# ime5_target_db register map
Vendor: Texas Instruments
Address unit: 16 bits
Registers are 32-bit, access per field, reset 0x0 unless marked. A register's access mark holds for its fields unless they carry their own. Offsets are as the file gives them; [hi:lo] are bit positions; {n}, {i} and the like mark numbered series; 'fields as' and 'values as' point back to an identical list.

## IME5 (part 2 of 3) — ipxact12_to_ccs_generated
0xF8C __ALL___Mbinfo_part2_MV1 rw — This register contains first motion vector for intermode winner
  [31:0] mvy_mvx — Motion vector
0xF90 __ALL___Mbinfo_part2_MV2 rw — This register contains Second motion vector for intermode winner
  [31:0] mvy_mvx — Motion vector
0xF94 __ALL___Mbinfo_part2_MV3 rw — This register contains Third motion vector for intermode winner
  [31:0] mvy_mvx — Motion vector
0xF98 __ALL___Mbinfo_part2_MV4 rw — This register contains fourth motion vector for intermode winner
  [31:0] mvy_mvx — Motion vector
0xF9C __ALL___Mbinfo_part2_MV5 rw — This register contains fifth motion vector for intermode winner
  [31:0] mvy_mvx — Motion vector
0xFA0 __ALL___Mbinfo_part2_MV6 rw — This register contains sixth motion vector for intermode winner
  [31:0] mvy_mvx — Motion vector
0xFA4 __ALL___Mbinfo_part2_MV7 rw — This register contains seventh motion vector for intermode winner
  [31:0] mvy_mvx — Motion vector
0xFA8 __ALL___Mbinfo_part2_MV8 rw — This register contains eighth motion vector for intermode winner
  [31:0] mvy_mvx — Motion vector
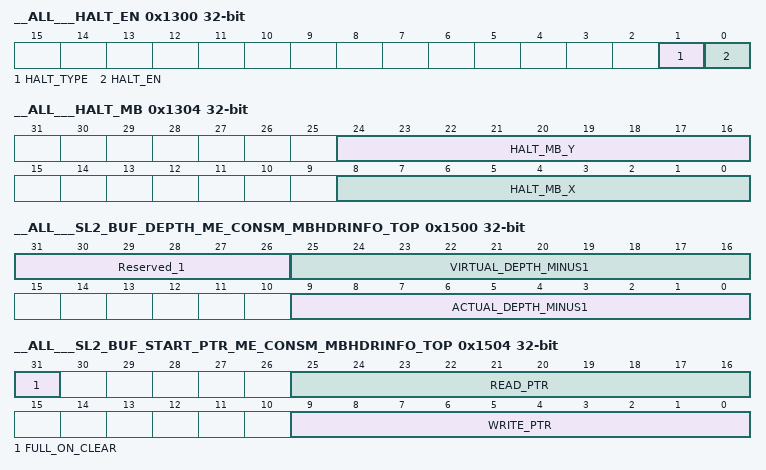
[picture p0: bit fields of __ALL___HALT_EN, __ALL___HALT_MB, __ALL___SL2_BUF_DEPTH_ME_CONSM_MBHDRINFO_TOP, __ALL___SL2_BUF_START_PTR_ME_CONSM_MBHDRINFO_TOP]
0x1300 __ALL___HALT_EN — HALT Enable Control Register
  [1] HALT_TYPE rw — 0: HALT in the beginning; 1: HALT in the end
  [0] HALT_EN rw — Is X-Y HALT enabled
0x1304 __ALL___HALT_MB — HALT MB Register
  [24:16] HALT_MB_Y rw — Y Position of Halt MB
  [8:0] HALT_MB_X rw — X Position of Halt MB
0x1320 __ALL___Debug_1 ro — ME5 Specific Debug Register 1??
0x1400 __ALL___SL2_BUF_ADDR_ME_CONSM_MBHDRINFO_TOP
  [22:0] ADDR rw
0x1404 __ALL___SL2_BUF_ADDR_ME_CONSM_TOP_NEIGHB_MVDATA
  [22:0] ADDR rw
0x1408 __ALL___SL2_BUF_ADDR_ME_PROD_MBINFO_PART1
  [22:0] ADDR rw
0x140C __ALL___SL2_BUF_ADDR_ME_PROD_MBINFO_PART2
  [22:0] ADDR rw
0x1410 __ALL___SL2_BUF_ADDR_ME_PROD_REF_SKIP
  [22:0] ADDR rw
0x1414 __ALL___SL2_BUF_ADDR_ME_CONSM_RL_MBINFO
  [22:0] ADDR rw
0x1418 __ALL___SL2_BUF_ADDR_ME_CONSM_RL_CSRS
  [22:0] ADDR rw
0x141C __ALL___SL2_BUF_ADDR_ME_CONSM_ORG_TILED_YUV_TOP
  [22:0] ADDR rw — Note that for CMB, there is no SL2BC inside ME5, since ME5 is not the last consumer. However, ME5 will still have the base address and read pointer registers.
0x1420 __ALL___SL2_BUF_ADDR_ME_CONSM_ORG_TILED_YUV_BOTTOM
  [22:0] ADDR rw
0x1424 __ALL___SL2_BUF_ADDR_ME_PROD_SPARE_0
  [22:0] ADDR rw
0x1428 __ALL___SL2_BUF_ADDR_ME_PROD_SPARE_1
  [22:0] ADDR rw
{0x142C+4i} __ALL___SL2_BUF_ADDR_ME_CONSM_SPARE_{i} (i=0..2)
  [22:0] ADDR rw
0x1500 __ALL___SL2_BUF_DEPTH_ME_CONSM_MBHDRINFO_TOP
  [31:26] Reserved_1 ro — MBINFO BC related register from IPE5 to ME5
  [25:16] VIRTUAL_DEPTH_MINUS1 rw
  [9:0] ACTUAL_DEPTH_MINUS1 rw
0x1504 __ALL___SL2_BUF_START_PTR_ME_CONSM_MBHDRINFO_TOP
  [31] FULL_ON_CLEAR rw, [25:16] READ_PTR rw, [9:0] WRITE_PTR rw
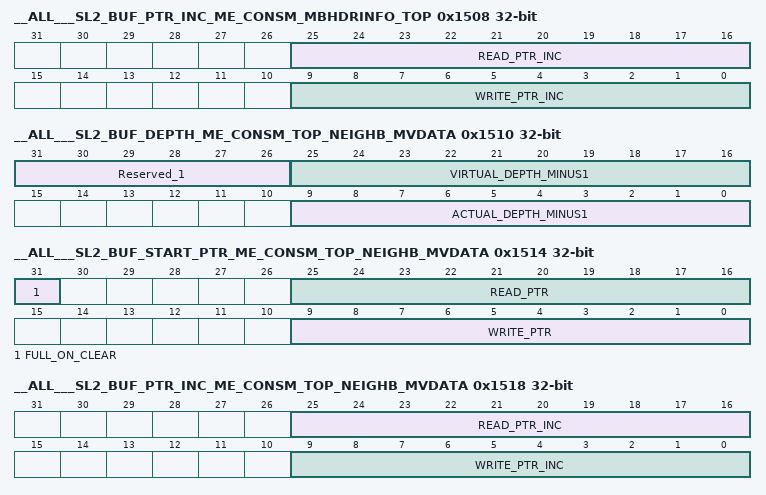
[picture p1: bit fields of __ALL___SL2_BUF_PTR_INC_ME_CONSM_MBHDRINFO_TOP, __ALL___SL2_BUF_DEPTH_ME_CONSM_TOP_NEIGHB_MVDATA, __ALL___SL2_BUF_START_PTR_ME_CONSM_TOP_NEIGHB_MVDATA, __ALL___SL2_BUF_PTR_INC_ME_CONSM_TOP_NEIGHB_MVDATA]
0x1508 __ALL___SL2_BUF_PTR_INC_ME_CONSM_MBHDRINFO_TOP
  [25:16] READ_PTR_INC rw, [9:0] WRITE_PTR_INC rw
0x1510 __ALL___SL2_BUF_DEPTH_ME_CONSM_TOP_NEIGHB_MVDATA
  [31:26] Reserved_1 ro — TOP MVP INFO BC related register from ECD5 to ME5
  [25:16] VIRTUAL_DEPTH_MINUS1 rw
  [9:0] ACTUAL_DEPTH_MINUS1 rw
0x1514 __ALL___SL2_BUF_START_PTR_ME_CONSM_TOP_NEIGHB_MVDATA
  [31] FULL_ON_CLEAR rw, [25:16] READ_PTR rw, [9:0] WRITE_PTR rw
0x1518 __ALL___SL2_BUF_PTR_INC_ME_CONSM_TOP_NEIGHB_MVDATA
  [25:16] READ_PTR_INC rw, [9:0] WRITE_PTR_INC rw
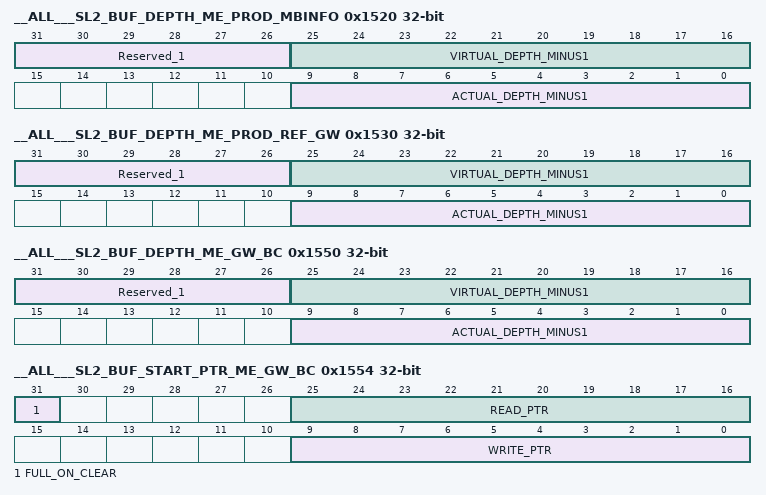
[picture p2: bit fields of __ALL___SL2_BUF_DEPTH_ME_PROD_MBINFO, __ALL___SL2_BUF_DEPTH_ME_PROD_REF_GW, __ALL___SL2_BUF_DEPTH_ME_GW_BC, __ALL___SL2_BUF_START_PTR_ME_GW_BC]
0x1520 __ALL___SL2_BUF_DEPTH_ME_PROD_MBINFO
  [31:26] Reserved_1 ro — MBINFO OUTPUT BC In producer sl2bcs, we don’t need start read pointer. Only start write pointer is required.
  [25:16] VIRTUAL_DEPTH_MINUS1 rw
  [9:0] ACTUAL_DEPTH_MINUS1 rw
0x1524 __ALL___SL2_BUF_START_PTR_ME_PROD_MBINFO
  [9:0] WRITE_PTR rw
0x1528 __ALL___SL2_BUF_PTR_INC_ME_PROD_MBINFO
  [9:0] WRITE_PTR_INC rw
0x1530 __ALL___SL2_BUF_DEPTH_ME_PROD_REF_GW
  [31:26] Reserved_1 ro — GW BC to MC In producer sl2bcs, we don’t need start read pointer. Only start write pointer is required.
  [25:16] VIRTUAL_DEPTH_MINUS1 rw
  [9:0] ACTUAL_DEPTH_MINUS1 rw
0x1534 __ALL___SL2_BUF_START_PTR_ME_PROD_REF_GW
  [9:0] WRITE_PTR rw
0x1538 __ALL___SL2_BUF_PTR_INC_ME_PROD_REF_GW
  [9:0] WRITE_PTR_INC rw
0x1550 __ALL___SL2_BUF_DEPTH_ME_GW_BC
  [31:26] Reserved_1 ro — Internal BC for GW between ME5 CORE and VIM thread
  [25:16] VIRTUAL_DEPTH_MINUS1 rw
  [9:0] ACTUAL_DEPTH_MINUS1 rw
0x1554 __ALL___SL2_BUF_START_PTR_ME_GW_BC
  [31] FULL_ON_CLEAR rw, [25:16] READ_PTR rw, [9:0] WRITE_PTR rw
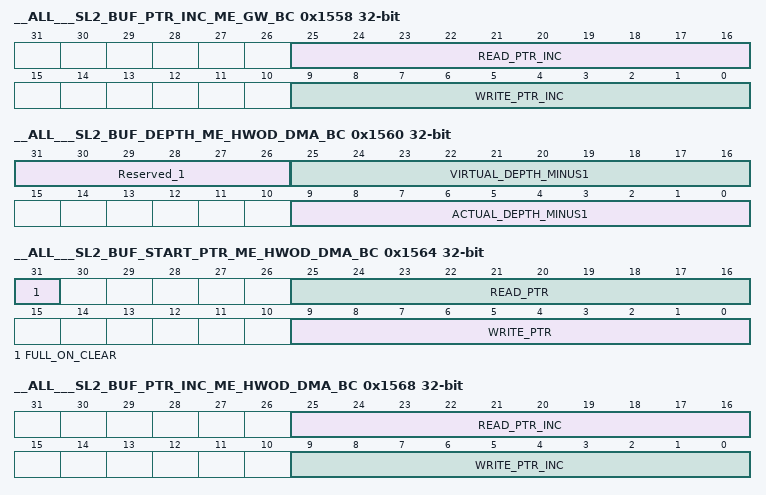
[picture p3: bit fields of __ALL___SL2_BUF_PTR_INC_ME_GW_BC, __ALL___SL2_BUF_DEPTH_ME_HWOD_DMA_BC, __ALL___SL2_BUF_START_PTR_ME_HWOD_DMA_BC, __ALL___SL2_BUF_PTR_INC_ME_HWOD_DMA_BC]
0x1558 __ALL___SL2_BUF_PTR_INC_ME_GW_BC
  [25:16] READ_PTR_INC rw, [9:0] WRITE_PTR_INC rw
0x1560 __ALL___SL2_BUF_DEPTH_ME_HWOD_DMA_BC
  [31:26] Reserved_1 ro — Internal BC for HWOD DMA between ME5 CORE and VIM thread
  [25:16] VIRTUAL_DEPTH_MINUS1 rw
  [9:0] ACTUAL_DEPTH_MINUS1 rw
0x1564 __ALL___SL2_BUF_START_PTR_ME_HWOD_DMA_BC
  [31] FULL_ON_CLEAR rw, [25:16] READ_PTR rw, [9:0] WRITE_PTR rw
0x1568 __ALL___SL2_BUF_PTR_INC_ME_HWOD_DMA_BC
  [25:16] READ_PTR_INC rw, [9:0] WRITE_PTR_INC rw
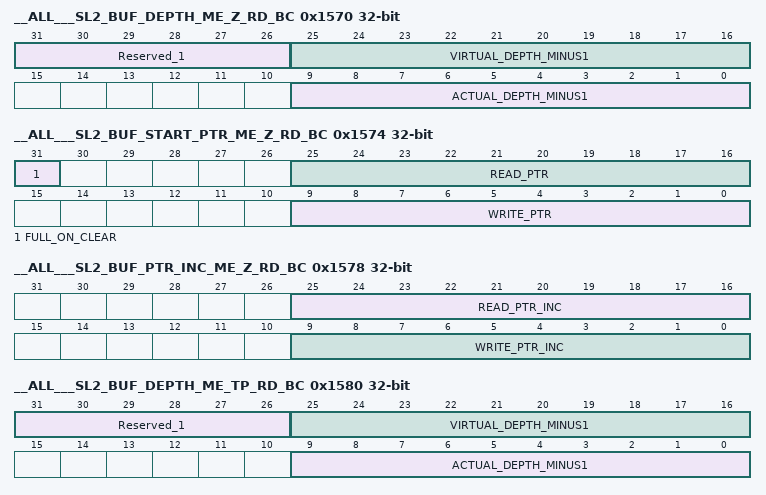
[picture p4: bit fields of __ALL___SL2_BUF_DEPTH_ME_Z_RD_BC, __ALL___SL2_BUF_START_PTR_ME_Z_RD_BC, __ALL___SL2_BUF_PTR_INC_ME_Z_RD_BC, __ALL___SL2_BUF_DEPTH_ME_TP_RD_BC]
0x1570 __ALL___SL2_BUF_DEPTH_ME_Z_RD_BC
  [31:26] Reserved_1 ro — Internal BC for ZFLAG Reads between ME5 CORE and VIM thread
  [25:16] VIRTUAL_DEPTH_MINUS1 rw
  [9:0] ACTUAL_DEPTH_MINUS1 rw
0x1574 __ALL___SL2_BUF_START_PTR_ME_Z_RD_BC
  [31] FULL_ON_CLEAR rw, [25:16] READ_PTR rw, [9:0] WRITE_PTR rw
0x1578 __ALL___SL2_BUF_PTR_INC_ME_Z_RD_BC
  [25:16] READ_PTR_INC rw, [9:0] WRITE_PTR_INC rw
0x1580 __ALL___SL2_BUF_DEPTH_ME_TP_RD_BC
  [31:26] Reserved_1 ro — Internal BC for TP Reads between ME5 CORE and VIM thread
  [25:16] VIRTUAL_DEPTH_MINUS1 rw
  [9:0] ACTUAL_DEPTH_MINUS1 rw
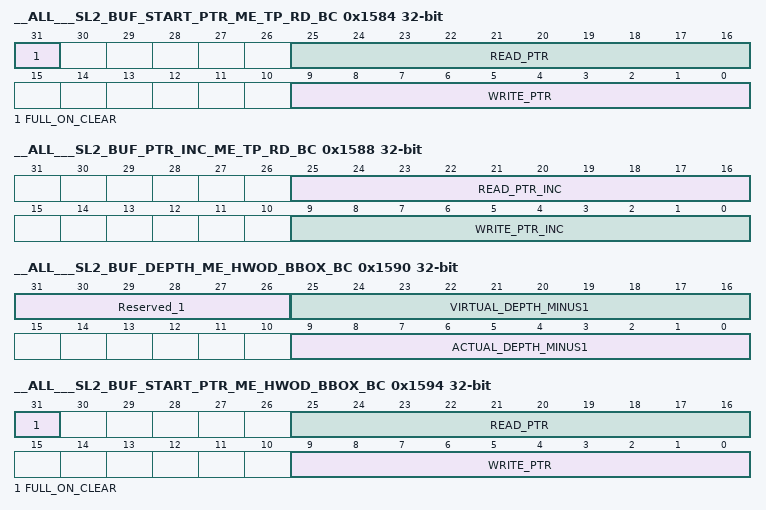
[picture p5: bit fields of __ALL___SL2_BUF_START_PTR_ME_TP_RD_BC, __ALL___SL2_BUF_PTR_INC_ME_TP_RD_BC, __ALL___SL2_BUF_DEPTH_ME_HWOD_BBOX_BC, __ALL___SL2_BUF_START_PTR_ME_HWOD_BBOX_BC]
0x1584 __ALL___SL2_BUF_START_PTR_ME_TP_RD_BC
  [31] FULL_ON_CLEAR rw, [25:16] READ_PTR rw, [9:0] WRITE_PTR rw
0x1588 __ALL___SL2_BUF_PTR_INC_ME_TP_RD_BC
  [25:16] READ_PTR_INC rw, [9:0] WRITE_PTR_INC rw
0x158C __ALL___SL2_BUF_RD_THRESHOLD_ME_TP_RD_BC
  [9:0] RD_THRESHOLD rw — bc_ready for the read side is asserted only if the number of filled BUFFER_ENTRYs is more than or equal to the rd_threshold. rd_threshold >= rd_pointer_inc
0x1590 __ALL___SL2_BUF_DEPTH_ME_HWOD_BBOX_BC
  [31:26] Reserved_1 ro — Internal BC for HWOD BOX between ME5 CORE and VIM thread
  [25:16] VIRTUAL_DEPTH_MINUS1 rw
  [9:0] ACTUAL_DEPTH_MINUS1 rw
0x1594 __ALL___SL2_BUF_START_PTR_ME_HWOD_BBOX_BC
  [31] FULL_ON_CLEAR rw, [25:16] READ_PTR rw, [9:0] WRITE_PTR rw
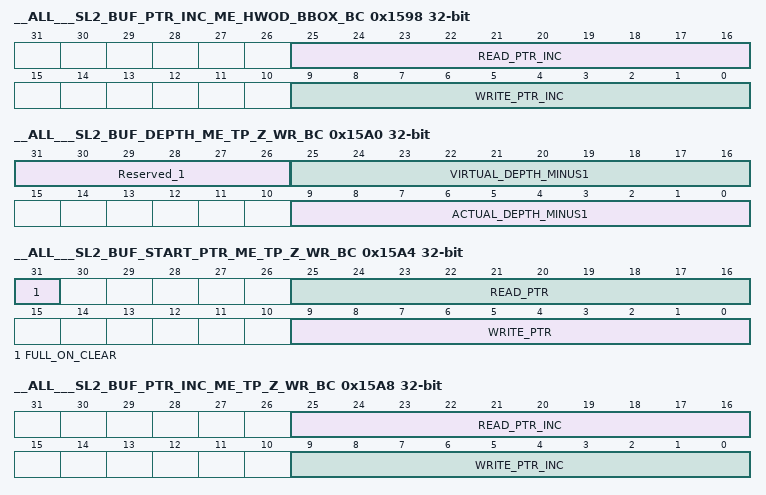
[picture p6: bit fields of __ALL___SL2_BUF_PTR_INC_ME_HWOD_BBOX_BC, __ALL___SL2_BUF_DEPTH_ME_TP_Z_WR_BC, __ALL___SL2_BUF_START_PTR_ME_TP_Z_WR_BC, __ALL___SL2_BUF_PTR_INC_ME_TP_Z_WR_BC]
0x1598 __ALL___SL2_BUF_PTR_INC_ME_HWOD_BBOX_BC
  [25:16] READ_PTR_INC rw, [9:0] WRITE_PTR_INC rw
0x15A0 __ALL___SL2_BUF_DEPTH_ME_TP_Z_WR_BC
  [31:26] Reserved_1 ro — Internal BC forZ flag writes as well as TP writes between ME5 CORE and VIM thread
  [25:16] VIRTUAL_DEPTH_MINUS1 rw
  [9:0] ACTUAL_DEPTH_MINUS1 rw
0x15A4 __ALL___SL2_BUF_START_PTR_ME_TP_Z_WR_BC
  [31] FULL_ON_CLEAR rw, [25:16] READ_PTR rw, [9:0] WRITE_PTR rw
0x15A8 __ALL___SL2_BUF_PTR_INC_ME_TP_Z_WR_BC
  [25:16] READ_PTR_INC rw, [9:0] WRITE_PTR_INC rw
0x15AC __ALL___SL2_BUF_RD_THRESHOLD_ME_TP_Z_WR_BC
  fields as __ALL___SL2_BUF_RD_THRESHOLD_ME_TP_RD_BC
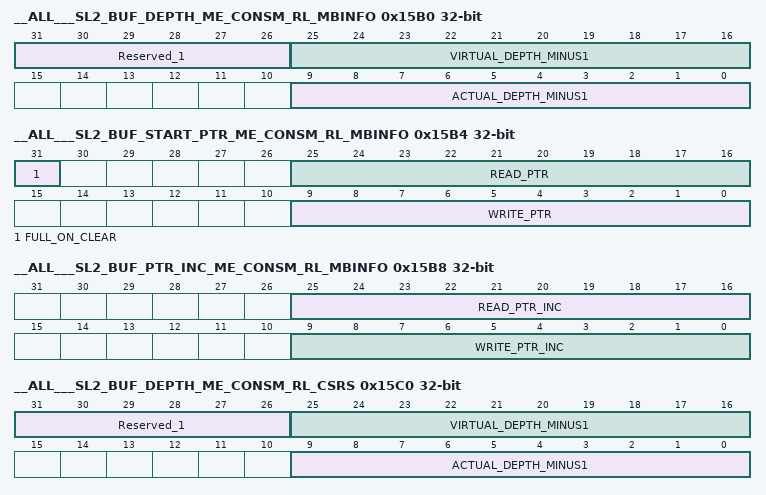
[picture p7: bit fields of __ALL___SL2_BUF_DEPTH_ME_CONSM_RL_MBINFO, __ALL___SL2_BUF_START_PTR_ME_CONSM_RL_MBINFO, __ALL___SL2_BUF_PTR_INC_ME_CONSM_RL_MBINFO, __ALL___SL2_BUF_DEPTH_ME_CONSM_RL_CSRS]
0x15B0 __ALL___SL2_BUF_DEPTH_ME_CONSM_RL_MBINFO
  [31:26] Reserved_1 ro — BC for SVC Reference Layer MBINFO
  [25:16] VIRTUAL_DEPTH_MINUS1 rw
  [9:0] ACTUAL_DEPTH_MINUS1 rw
0x15B4 __ALL___SL2_BUF_START_PTR_ME_CONSM_RL_MBINFO
  [31] FULL_ON_CLEAR rw, [25:16] READ_PTR rw, [9:0] WRITE_PTR rw
0x15B8 __ALL___SL2_BUF_PTR_INC_ME_CONSM_RL_MBINFO
  [25:16] READ_PTR_INC rw, [9:0] WRITE_PTR_INC rw
0x15C0 __ALL___SL2_BUF_DEPTH_ME_CONSM_RL_CSRS
  [31:26] Reserved_1 ro — BC for SVC Reference Layer Data
  [25:16] VIRTUAL_DEPTH_MINUS1 rw
  [9:0] ACTUAL_DEPTH_MINUS1 rw
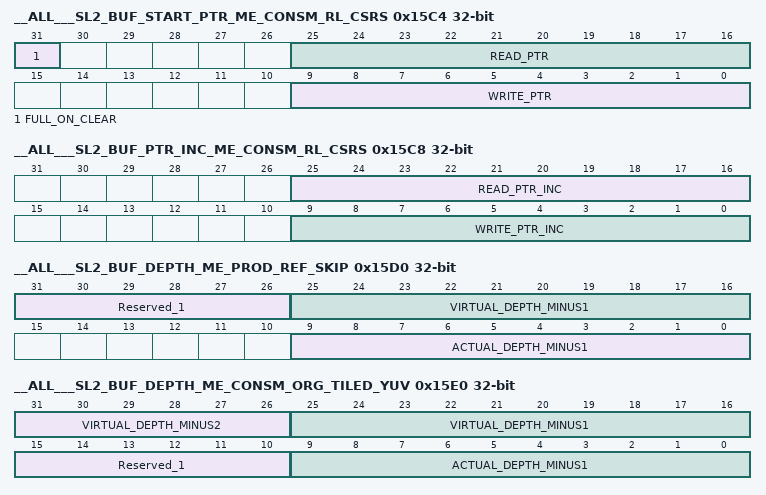
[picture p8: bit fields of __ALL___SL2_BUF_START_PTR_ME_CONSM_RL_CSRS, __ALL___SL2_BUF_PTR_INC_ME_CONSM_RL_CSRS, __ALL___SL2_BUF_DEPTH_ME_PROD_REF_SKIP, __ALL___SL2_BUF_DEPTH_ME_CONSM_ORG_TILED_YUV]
0x15C4 __ALL___SL2_BUF_START_PTR_ME_CONSM_RL_CSRS
  [31] FULL_ON_CLEAR rw, [25:16] READ_PTR rw, [9:0] WRITE_PTR rw
0x15C8 __ALL___SL2_BUF_PTR_INC_ME_CONSM_RL_CSRS
  [25:16] READ_PTR_INC rw, [9:0] WRITE_PTR_INC rw
0x15D0 __ALL___SL2_BUF_DEPTH_ME_PROD_REF_SKIP
  [31:26] Reserved_1 ro — BC for SKOB output from ME to MC
  [25:16] VIRTUAL_DEPTH_MINUS1 rw
  [9:0] ACTUAL_DEPTH_MINUS1 rw
0x15D4 __ALL___SL2_BUF_START_PTR_ME_PROD_REF_SKIP
  [9:0] WRITE_PTR rw
0x15D8 __ALL___SL2_BUF_PTR_INC_ME_PROD_REF_SKIP
  [9:0] WRITE_PTR_INC rw
0x15E0 __ALL___SL2_BUF_DEPTH_ME_CONSM_ORG_TILED_YUV
  [31:26] VIRTUAL_DEPTH_MINUS2 ro
  [25:16] VIRTUAL_DEPTH_MINUS1 rw
  [15:10] Reserved_1 ro — BC related registers for CMB. There is no BC exists Size by which READ_PTR of to be incremented on the falling edge of rd_core_busy
  [9:0] ACTUAL_DEPTH_MINUS1 rw
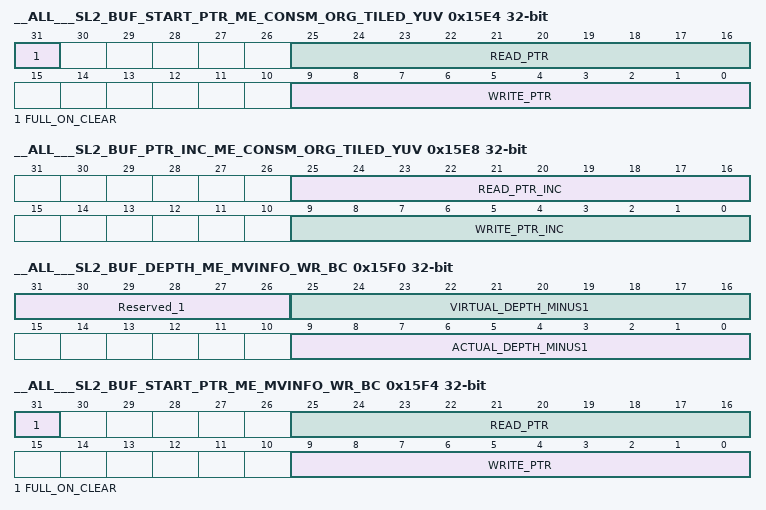
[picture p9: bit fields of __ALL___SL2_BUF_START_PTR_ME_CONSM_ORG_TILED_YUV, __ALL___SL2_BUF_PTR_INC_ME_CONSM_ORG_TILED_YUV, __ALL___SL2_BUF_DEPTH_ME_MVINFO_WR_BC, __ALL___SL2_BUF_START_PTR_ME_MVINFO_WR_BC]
0x15E4 __ALL___SL2_BUF_START_PTR_ME_CONSM_ORG_TILED_YUV
  [31] FULL_ON_CLEAR rw, [25:16] READ_PTR rw, [9:0] WRITE_PTR rw
0x15E8 __ALL___SL2_BUF_PTR_INC_ME_CONSM_ORG_TILED_YUV
  [25:16] READ_PTR_INC rw, [9:0] WRITE_PTR_INC rw
0x15F0 __ALL___SL2_BUF_DEPTH_ME_MVINFO_WR_BC
  fields as __ALL___SL2_BUF_DEPTH_ME_GW_BC
0x15F4 __ALL___SL2_BUF_START_PTR_ME_MVINFO_WR_BC
  [31] FULL_ON_CLEAR rw, [25:16] READ_PTR rw, [9:0] WRITE_PTR rw
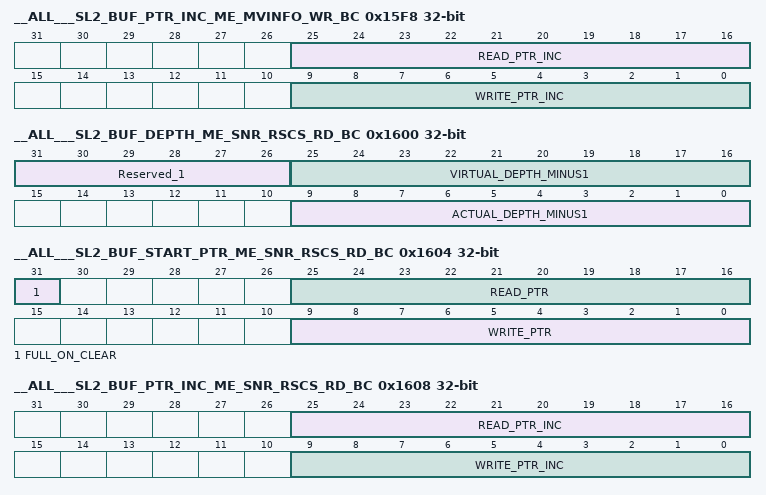
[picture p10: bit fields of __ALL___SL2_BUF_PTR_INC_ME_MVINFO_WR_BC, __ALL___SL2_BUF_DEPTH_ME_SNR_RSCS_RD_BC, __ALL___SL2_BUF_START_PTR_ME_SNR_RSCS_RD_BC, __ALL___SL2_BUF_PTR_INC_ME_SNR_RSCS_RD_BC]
0x15F8 __ALL___SL2_BUF_PTR_INC_ME_MVINFO_WR_BC
  [25:16] READ_PTR_INC rw, [9:0] WRITE_PTR_INC rw
0x1600 __ALL___SL2_BUF_DEPTH_ME_SNR_RSCS_RD_BC
  fields as __ALL___SL2_BUF_DEPTH_ME_GW_BC
0x1604 __ALL___SL2_BUF_START_PTR_ME_SNR_RSCS_RD_BC
  [31] FULL_ON_CLEAR rw, [25:16] READ_PTR rw, [9:0] WRITE_PTR rw
0x1608 __ALL___SL2_BUF_PTR_INC_ME_SNR_RSCS_RD_BC
  [25:16] READ_PTR_INC rw, [9:0] WRITE_PTR_INC rw
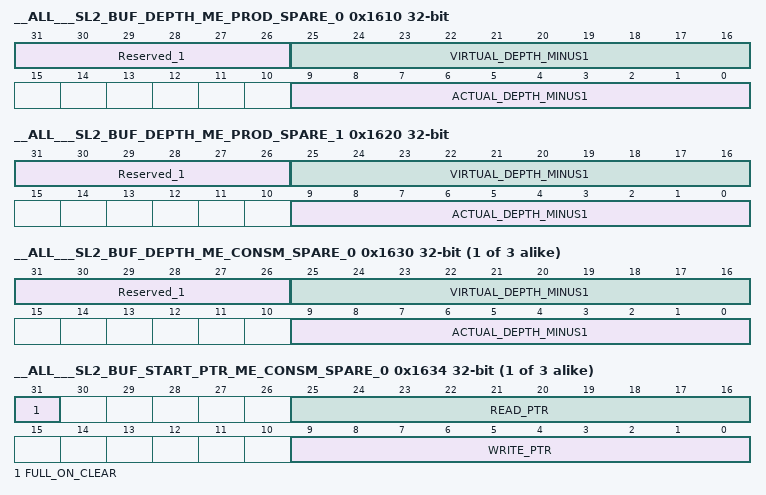
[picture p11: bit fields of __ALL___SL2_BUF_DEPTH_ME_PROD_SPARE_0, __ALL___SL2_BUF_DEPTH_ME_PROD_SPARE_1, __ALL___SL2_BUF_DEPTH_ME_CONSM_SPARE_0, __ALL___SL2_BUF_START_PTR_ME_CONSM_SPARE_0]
0x1610 __ALL___SL2_BUF_DEPTH_ME_PROD_SPARE_0
  [31:26] Reserved_1 ro — Spare BC for Producer
  [25:16] VIRTUAL_DEPTH_MINUS1 rw
  [9:0] ACTUAL_DEPTH_MINUS1 rw
0x1614 __ALL___SL2_BUF_START_PTR_ME_PROD_SPARE_0
  [9:0] WRITE_PTR rw
0x1618 __ALL___SL2_BUF_PTR_INC_ME_PROD_SPARE_0
  [9:0] WRITE_PTR_INC rw
0x1620 __ALL___SL2_BUF_DEPTH_ME_PROD_SPARE_1
  fields as __ALL___SL2_BUF_DEPTH_ME_PROD_SPARE_0
0x1624 __ALL___SL2_BUF_START_PTR_ME_PROD_SPARE_1
  [9:0] WRITE_PTR rw
0x1628 __ALL___SL2_BUF_PTR_INC_ME_PROD_SPARE_1
  [9:0] WRITE_PTR_INC rw
{0x1630+0x10*i} __ALL___SL2_BUF_DEPTH_ME_CONSM_SPARE_{i} (i=0..2)
  [31:26] Reserved_1 ro — Spare BC for Consumer
  [25:16] VIRTUAL_DEPTH_MINUS1 rw
  [9:0] ACTUAL_DEPTH_MINUS1 rw
{0x1634+0x10*i} __ALL___SL2_BUF_START_PTR_ME_CONSM_SPARE_{i} (i=0..2)
  [31] FULL_ON_CLEAR rw, [25:16] READ_PTR rw, [9:0] WRITE_PTR rw
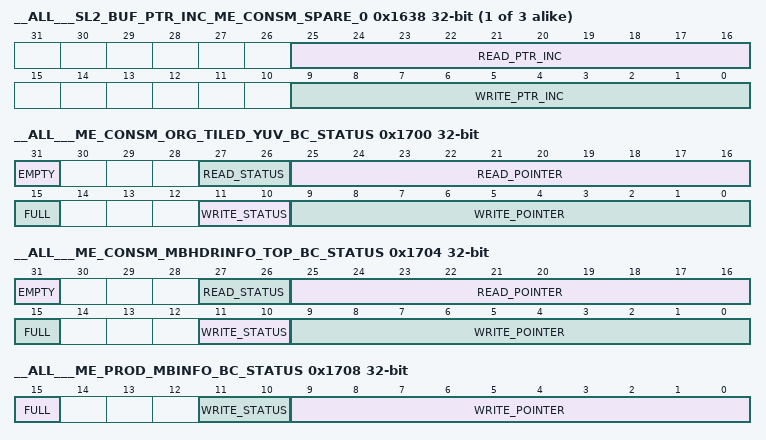
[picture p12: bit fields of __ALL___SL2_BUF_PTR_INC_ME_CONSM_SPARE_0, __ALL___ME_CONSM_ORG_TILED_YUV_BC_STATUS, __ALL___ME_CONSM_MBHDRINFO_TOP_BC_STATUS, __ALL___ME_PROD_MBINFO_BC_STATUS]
{0x1638+0x10*i} __ALL___SL2_BUF_PTR_INC_ME_CONSM_SPARE_{i} (i=0..2)
  [25:16] READ_PTR_INC rw, [9:0] WRITE_PTR_INC rw
0x1700 __ALL___ME_CONSM_ORG_TILED_YUV_BC_STATUS ro
  [31] EMPTY, [27:26] READ_STATUS, [25:16] READ_POINTER, [15] FULL, [11:10] WRITE_STATUS, [9:0] WRITE_POINTER
0x1704 __ALL___ME_CONSM_MBHDRINFO_TOP_BC_STATUS ro
  fields as __ALL___ME_CONSM_ORG_TILED_YUV_BC_STATUS
0x1708 __ALL___ME_PROD_MBINFO_BC_STATUS ro
  [15] FULL, [11:10] WRITE_STATUS, [9:0] WRITE_POINTER
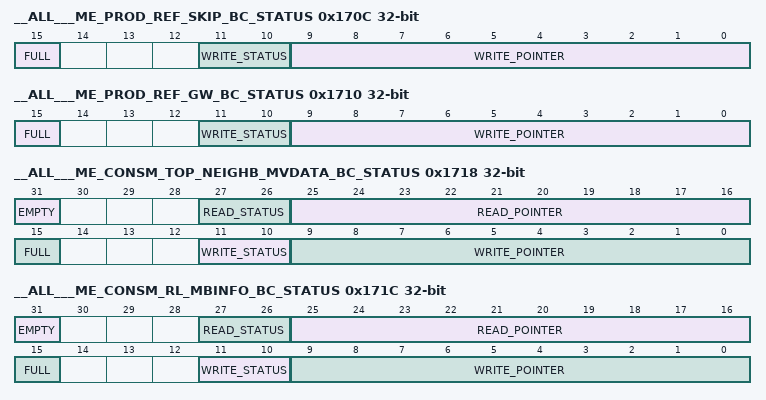
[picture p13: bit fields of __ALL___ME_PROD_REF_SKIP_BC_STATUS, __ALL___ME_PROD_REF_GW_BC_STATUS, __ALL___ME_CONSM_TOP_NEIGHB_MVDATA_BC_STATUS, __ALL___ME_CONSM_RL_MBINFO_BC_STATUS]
0x170C __ALL___ME_PROD_REF_SKIP_BC_STATUS ro
  [15] FULL, [11:10] WRITE_STATUS, [9:0] WRITE_POINTER
0x1710 __ALL___ME_PROD_REF_GW_BC_STATUS ro
  [15] FULL, [11:10] WRITE_STATUS, [9:0] WRITE_POINTER
0x1718 __ALL___ME_CONSM_TOP_NEIGHB_MVDATA_BC_STATUS ro
  fields as __ALL___ME_CONSM_ORG_TILED_YUV_BC_STATUS
0x171C __ALL___ME_CONSM_RL_MBINFO_BC_STATUS ro
  fields as __ALL___ME_CONSM_ORG_TILED_YUV_BC_STATUS
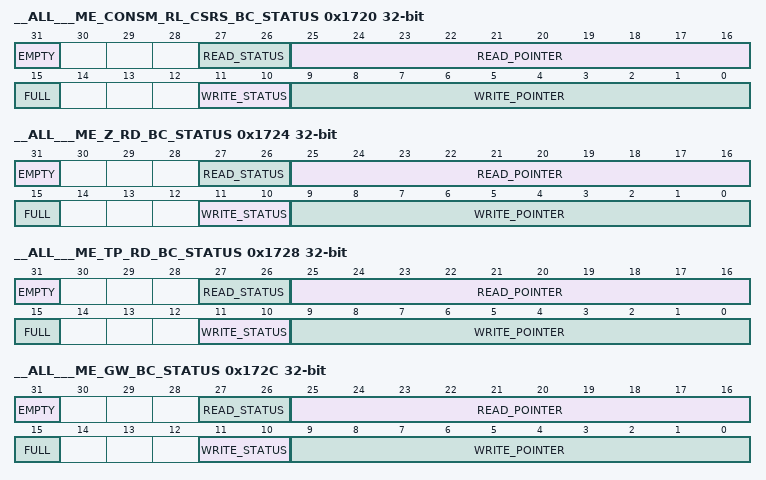
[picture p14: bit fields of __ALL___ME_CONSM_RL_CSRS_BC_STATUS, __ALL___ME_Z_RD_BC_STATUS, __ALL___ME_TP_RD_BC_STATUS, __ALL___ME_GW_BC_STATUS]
0x1720 __ALL___ME_CONSM_RL_CSRS_BC_STATUS ro
  fields as __ALL___ME_CONSM_ORG_TILED_YUV_BC_STATUS
0x1724 __ALL___ME_Z_RD_BC_STATUS ro
  fields as __ALL___ME_CONSM_ORG_TILED_YUV_BC_STATUS
0x1728 __ALL___ME_TP_RD_BC_STATUS ro
  fields as __ALL___ME_CONSM_ORG_TILED_YUV_BC_STATUS
0x172C __ALL___ME_GW_BC_STATUS ro
  fields as __ALL___ME_CONSM_ORG_TILED_YUV_BC_STATUS
0x1730 __ALL___ME_HWOD_BBOX_BC_STATUS ro
  fields as __ALL___ME_CONSM_ORG_TILED_YUV_BC_STATUS
0x1734 __ALL___ME_HWOD_DMA_BC_STATUS ro
  fields as __ALL___ME_CONSM_ORG_TILED_YUV_BC_STATUS
0x1738 __ALL___ME_Z_WR_BC_STATUS ro
  fields as __ALL___ME_CONSM_ORG_TILED_YUV_BC_STATUS
0x173C __ALL___ME_SNR_RSCS_RD_BC_STATUS ro
  fields as __ALL___ME_CONSM_ORG_TILED_YUV_BC_STATUS
0x1740 __ALL___ME_MVINFO_WR_BC_STATUS ro
  fields as __ALL___ME_CONSM_ORG_TILED_YUV_BC_STATUS
0x1744 __ALL___ME_PROD_SPARE_0_BC_STATUS ro
  [15] FULL, [11:10] WRITE_STATUS, [9:0] WRITE_POINTER
0x1748 __ALL___ME_PROD_SPARE_1_BC_STATUS ro
  [15] FULL, [11:10] WRITE_STATUS, [9:0] WRITE_POINTER
{0x174C+4i} __ALL___ME_CONSM_SPARE_{i}_BC_STATUS ro (i=0..2)
  fields as __ALL___ME_CONSM_ORG_TILED_YUV_BC_STATUS
0x1800 __ALL___PID ro — ME5 PID
0x1804 __ALL___SYSCONFIG
  [5:4] STANDBYMODE rw
  [3:2] IDLE_MODE rw
  [1] FREE_EMU rw — sensitivity to emulation suspend (suspend is same as halt?)
  [0] SOFT_RESET rw
0x1808 __ALL___IRQ_EOI ro
  [0] IRQ_EOI
0x180C __ALL___IRQ_STATUS_RAW
  [23] DM_DONE rw, [22] MB_COUNT_INT_2 rw, [21] MB_COUNT_INT_1 rw, [20] GW_nMB_Done rw, [19] END_OF_MB rw, [18] END_OF_PIPE rw, [17] END_OF_SLICE rw, [16] END_OF_ROW rw, [15:8] GPI9_16 rw, [7:1] GPI2_8 rw, [0] GPI1 rw
0x1810 __ALL___IRQ_STATUS
  fields as __ALL___IRQ_STATUS_RAW
0x1814 __ALL___IRQ_ENABLE_SET
  fields as __ALL___IRQ_STATUS_RAW
0x1818 __ALL___IRQ_ENABLE_CLR
  fields as __ALL___IRQ_STATUS_RAW
0x181C __ALL___IRQ_BLOCKING_CFG
  fields as __ALL___IRQ_STATUS_RAW
0x1820 __ALL___CFPB_START — CFPB Start Address
  [22:0] FPB_start rw
0x1824 __ALL___SCHEDULER_STATUS ro — Shedulaer Status
  [20] STEPPING, [19] RESUMING, [18] HALTED, [17] CPU_HALTING, [16] THRD_HALTING, [12] RESUME_ACK, [11] RESUME, [10] REWIND, [9] WAIT_4_FUNC_IDLE, [8] EOP, [3] THREAD_EXE, [2] INIT_ACK, [1] HWA_INIT, [0] FUNC_IDLE
0x1828 __ALL___HWA_THREAD_STATUS_CORE ro — Thread Status for core thread
  [7] HALT_ABORT, [6] HALT_DEBUG, [5] HALT_REWIND, [4] HALT_PIPEDOWN, [3] HALT_INTR, [2] EXE, [1] WAIT, [0] IDLE
0x182C __ALL___HWA_THREAD_STATUS_PREFETCH ro — Thread Status for prefetch thread
  fields as __ALL___HWA_THREAD_STATUS_CORE
0x1830 __ALL___HWA_THREAD_STATUS_Z_RD ro — Thread Status for Z_RD thread
  fields as __ALL___HWA_THREAD_STATUS_CORE
0x1834 __ALL___HWA_THREAD_STATUS_TP_RD ro — Thread Status for TP_RD thread
  fields as __ALL___HWA_THREAD_STATUS_CORE
0x1838 __ALL___HWA_THREAD_STATUS_TP_Z_WR ro — Thread Status for TP Z WR thread
  fields as __ALL___HWA_THREAD_STATUS_CORE
0x183C __ALL___HWA_THREAD_STATUS_HWOD_BBOX ro — Thread Status for HWOD_BBOX thread
  fields as __ALL___HWA_THREAD_STATUS_CORE
0x1840 __ALL___HWA_THREAD_STATUS_GW ro — Thread Status for GW thread
  fields as __ALL___HWA_THREAD_STATUS_CORE
0x1844 __ALL___HWA_THREAD_STATUS_HWOD_DMA ro — Thread Status for HWOD DMA thread
  fields as __ALL___HWA_THREAD_STATUS_CORE
0x1848 __ALL___HWA_THREAD_STATUS_MVINFO ro — Thread Status for RL MVINFO thread
  fields as __ALL___HWA_THREAD_STATUS_CORE
0x184C __ALL___HWA_THREAD_STATUS_SNR_RSCS ro — Thread Status for SNR RS CS thread
  fields as __ALL___HWA_THREAD_STATUS_CORE
0x1880 __ALL___ME5_ARP32_RESET — ME5 T16 reset control
  [0] ME5_ARP32_reset rw
0x1884 __ALL___BC_CLEAR — BC clear register for SL2BC
  [19] ME_CONSM_ORG_TILED_YUV_BC_CLEAR wo, [18] ME_CONSM_MBHDRINFO_TOP_BC_CLEAR wo, [17] ME_PROD_MBINFO_BC_CLEAR wo, [16] ME_PROD_REF_SKIP_BC_CLEAR wo, [15] ME_PROD_REF_GW_BC_CLEAR wo, [13] ME_CONSM_TOP_NEIGHB_MVDATA_BC_CLEAR wo, [12] ME_CONSM_SPARE_0_BC_CLEAR wo, [11] ME_CONSM_SPARE_1_BC_CLEAR wo, [10] ME_CONSM_SPARE_2_BC_CLEAR wo, [9] ME_PROD_SPARE_0_BC_CLEAR wo, [8] ME_PROD_SPARE_1_BC_CLEAR wo, [7] ME_CONSM_RL_MBINFO_BC_CLEAR wo, [6] ME_CONSM_RL_CSRS_BC_CLEAR wo, [5] ME_Z_RD_BC_CLEAR wo, [4] ME_TP_RD_BC_CLEAR wo, [3] ME_GW_BC_CLEAR wo, [2] ME_HWOD_BBOX_BC_CLEAR wo, [1] ME_HWOD_DMA_BC_CLEAR wo, [0] ME_Z_WR_BC_CLEAR wo
0x1888 __ALL___BC_ENABLE — BC ENABLE register for SL2BC
  [19] ME_CONSM_ORG_TILED_YUV_BC_ENABLE rw, [18] ME_CONSM_MBHDRINFO_TOP_BC_ENABLE rw, [17] ME_PROD_MBINFO_BC_ENABLE rw, [16] ME_PROD_REF_SKIP_BC_ENABLE rw, [15] ME_PROD_REF_GW_BC_ENABLE rw, [13] ME_CONSM_TOP_NEIGHB_MVDATA_BC_ENABLE rw, [12] ME_CONSM_SPARE_0_BC_ENABLE rw, [11] ME_CONSM_SPARE_1_BC_ENABLE rw, [10] ME_CONSM_SPARE_2_BC_ENABLE rw, [9] ME_PROD_SPARE_0_BC_ENABLE rw, [8] ME_PROD_SPARE_1_BC_ENABLE rw, [7] ME_CONSM_RL_MBINFO_BC_ENABLE rw, [6] ME_CONSM_RL_CSRS_BC_ENABLE rw, [5] ME_Z_RD_BC_ENABLE rw, [4] ME_TP_RD_BC_ENABLE rw, [3] ME_GW_BC_ENABLE rw, [2] ME_HWOD_BBOX_BC_ENABLE rw, [1] ME_HWOD_DMA_BC_ENABLE rw, [0] ME_Z_WR_BC_ENABLE rw
0x188C __ALL___BC_IDLE — BC IDLEregister for SL2BC
  [19] ME_CONSM_ORG_TILED_YUV_BC_IDLE rw, [18] ME_CONSM_MBHDRINFO_TOP_BC_IDLE rw, [17] ME_PROD_MBINFO_BC_IDLE rw, [16] ME_PROD_REF_SKIP_BC_IDLE rw, [15] ME_PROD_REF_GW_BC_IDLE rw, [14] ME_PROD_REF_HWOD_BC_IDLE ro, [13] ME_CONSM_TOP_NEIGHB_MVDATA_BC_IDLE rw, [12] ME_CONSM_SPARE_0_BC_IDLE rw, [11] ME_CONSM_SPARE_1_BC_IDLE rw, [10] ME_CONSM_SPARE_2_BC_IDLE rw, [9] ME_PROD_SPARE_0_BC_IDLE rw, [8] ME_PROD_SPARE_1_BC_IDLE rw, [7] ME_CONSM_RL_MBINFO_BC_IDLE rw, [6] ME_CONSM_RL_CSRS_BC_IDLE rw, [5] ME_Z_RD_BC_IDLE rw, [4] ME_TP_RD_BC_IDLE rw, [3] ME_GW_BC_IDLE rw, [2] ME_HWOD_BBOX_BC_IDLE rw, [1] ME_HWOD_DMA_BC_IDLE rw, [0] ME_Z_WR_BC_IDLE rw
0x1890 __ALL___MBINDEX — Internal MBIndex registers
  [17:9] ColIndex rw — Internal Column Index
  [8:0] RowIndex rw — Internal Rowindex
0x1894 __ALL___MB_COUNT_CTRL1 — Control register to generate interrupt after N MB
  [31] EN rw — To enable or disable the counter to generate interrupt after N MB
  [17:0] MAX_COUNT rw — Number of MBs, after which interrupt needs to be generated. ( if 1, interrupt generated every MB ); MAX_COUNT of 0 is illegal; EN bit should be 0 if MAX_COUNT = 0.
0x1898 __ALL___MB_COUNT_CTRL2 — Control register to generate interrupt after N MB
  fields as __ALL___MB_COUNT_CTRL1
0x189C __ALL___EXT_EVENT — iCONT can write to this register to allow ME5 resume execution after ME5 has executed ‘WFE ext_event1’ instruction. Can be used as a debug mechanism. The register always reads a zero. A single cycle pulse event is generated upon writing ‘1’ by iCONT.
  [0] Ext_Event1 rw — External Event fro iCont
0x18A0 __ALL___CORE_STATUS ro
  [31:2] RESERVED — Core status register
  [1] Core_in_WaitForGrant
  [0] Core_in_WaitForInit
0x18A4 __ALL___RFPB_START — RFPB Start Address
  [22:0] FPB_start rw
0x18A8 __ALL___ME5_SEM_COUNT0 — General purpose counter for SW use. SEM_COUNT1_NZ event will be set whenever the counter value is non-zero. Typically used for semaphore between CPUs, HWA via interrupt and/or events or polling.
  [9] dec_me5_sem_count rw — This bit when set will clear the contents of the counter. The counter will not overflow from 0. This bit is autocleared. Note that SW write to this register should have only one of the 2 control bit set.
  [8] inc_me5_sem_count rw — This bit when set will increment the contents of the counter. The counter will not overflow to 0. This bit is autocleared. Note that SW write to this register should have only one of the 2 control bit set.
  [7:0] me5_sem_count_value ro — Provides the current value of the counter. Counter value if updated based on the following SW writes 1) Decrements by 1 till it reaches 0 when DEC_COUNT bitfield is set to 1. 2) Increments by 1 till it reaches all-ones count when INC_COUNT bitfield is set to 1.
0x18AC __ALL___ME5_SEM_COUNT1 — General purpose counter for SW use. SEM_COUNT0_NZ event will be set whenever the counter value is non-zero. Typically used for semaphore between CPUs, HWA via interrupt and/or events or polling.
  fields as __ALL___ME5_SEM_COUNT0
0x1900 __ALL___MBINFO_IN_PART1_0 rw — IPRED_MODE[15} to IPRED_MODE[8]
  [31:0] IPRED_MODE15_8 — part1 of MBinfo only
0x1904 __ALL___MBINFO_IN_PART1_1 rw — IPRED_MODE[7} to IPRED_MODE[0]
  [31:0] IPRED_MODE_7_0
0x1908 __ALL___MBINFO_IN_PART1_2 rw — mb_type, tr8x8, qp values from ipe and other misc fields
  [31:30] mb_type
  [29] tr8x8
  [28] mb_field
  [21] end_of_pipe
  [11:0] MQScale — Modified Qscale
0x190C __ALL___MBINFO_IN_PART1_3 rw — Cond_mbskip and other fields from IPE
  [31:30] c_ipred_mode
  [28] force_cbp_zero — Indicates zero residual to CALC and skip to IME
  [27] pic_bound_b
  [26] pic_bound_r
  [25] pic_bound_u
  [24] pic_bound_l
  [23] mb_ur_avail
  [22] mb_uu_avail
  [21] mb_ul_avail
  [20] mb_ll_avail
  [19] start_of_slice
  [18] end_of_slice
  [17:9] ColumnIndex
  [8:0] RowIndex
0x1910 __ALL___MBINFO_IN_PART2_0 rw — Reserved Regsiter
0x1914 __ALL___MBINFO_IN_ROI rw
  [4] Use_alternate_weights_for_mb, [3:0] RegionIdx
0x1918 __ALL___MBINFO_IN_QSCALEQ4 rw
  [23:12] BASE_QSCALEQ4, [11:0] IPE_QSCALE_Q4
0x191C __ALL___MBINFO_IN_INTRCOST rw
  [31:18] RESERVED — n= bits per pixel
  [17:0] COST
0x1920 __ALL___MBINFO_P2_PART1_0 rw — IPRED_MODE[15} to IPRED_MODE[8]
  [31:0] IPRED_MODE15_8 — part1 of MBinfo only
0x1924 __ALL___MBINFO_P2_PART1_1 rw — IPRED_MODE[7} to IPRED_MODE[0]
  [31:0] IPRED_MODE_7_0
0x1928 __ALL___MBINFO_P2_PART1_2 rw — mb_type, tr8x8, qp values from ipe and other misc fields
  fields as __ALL___MBINFO_IN_PART1_2
0x192C __ALL___MBINFO_P2_PART1_3 rw — Cond_mbskip and other fields from IPE
  [31:30] c_ipred_mode, [28] error_flag, [27] pic_bound_b, [26] pic_bound_r, [25] pic_bound_u, [24] pic_bound_l, [23] mb_ur_avail, [22] mb_uu_avail, [21] mb_ul_avail, [20] mb_ll_avail, [19] start_of_slice, [18] end_of_slice, [17:9] ColumnIndex, [8:0] RowIndex
0x1930 __ALL___MBINFO_P2_PART2_0 rw — Reserved Regsiter
0x1934 __ALL___MBINFO_P2_ROI rw
  [4] Use_alternate_weights_for_mb, [3:0] RegionIdx
0x1938 __ALL___MBINFO_P2_QSCALEQ4 rw
  [23:12] BASE_QSCALEQ4, [11:0] IPE_QSCALE_Q4
0x193C __ALL___MBINFO_P2_INTRCOST rw
  [31:18] RESERVED — n= bits per pixel
  [17:0] COST
0x1940 __ALL___CORE_INIT rw
  [31:1] RESERVED — Core init done register to be programmed by ME5 ARP32 to indicate HTS that initilization is done
  [0] core_init_doe
0x1944 __ALL___CORE_TEND rw
  [31:1] RESERVED — Core Tend register to be programmed by ME5 ARP32 to indicate HTS that T end
  [0] core_Tend
0x1948 __ALL___CORE_STATUS rw
  fields as __ALL___CORE_STATUS
0x194C __ALL___LOOP_EXIT rw
  [31:1] RESERVED — Loop exit condition register to be set by ME5 C-model. OR of following (some of them are qualified) : EOR, EOS, EOP, rewind, GW_nMB_done
  [0] loop_exit
0x1950 __ALL___RESUME rw — resume event from HTS registered. Set to ‘1’ by HTS on resume event. ME5 cpu clears it by writing ‘1’. When ME5 writes ‘1’ to this register, resume_done pulse is also sent to HTS.
  [0] Resume — Rewind event registered
0x1954 __ALL___FUNC_IDLE_EVENT rw
  [0] Force_func_idle — Registered force_func_idle event
0x1958 __ALL___REWIND_MB_START rw
  [17:0] MBIndex_rewind_start — Last valid macro-block processed before rewind. Default value is -1. This register is updated by software during rewind processing. Statistics collection is disabled by ME5 hardware when MBIndex of current MB MBIndex_rewind_start. MBIndex of current MB is the index of pipe2 MB in 2 MB pipeline mode. Otherwise it is the index in input MBInfo.
0x195C __ALL___NEXT_MBLOOP_TYPE — Used for selection of BC glue for Tstart_req generation. Written by ME5 ARP32
  [1:0] Next_MB_LoopType rw — Next MB loop type. Valid only in 2 MB pipe line mode
0x1968 __ALL___PREFECTH_THD_ENABLE — Enable register for prefetch thread
  [31:1] RESERVED ro — Points to either A(=0) or B(=1). iCONT needs to read this to find out MBinfo corresponding to current MB.
  [0] PFT_THD_EN rw — When write to one BC glue generates Tstart request for prefecth thread. When zero bc glue masks prefecth thread
0x1980 __ALL___NUM_STATIC_MBS
  [31:19] RESERVED ro — Count of static MBs in the frame. A static MB has a small motion vector in both x and y direction. (Separate thresholds to be used for x and y). This statistic is accumulation of IsStatic flag in the MB level statistic. motion vector used for calculating the stats is defined as follows: 1. For P frame, if skip mode is winner, skip motion vector is used 2. For P frame, if winner is other than skip, then, best inter 16x16 partition mv is used Note that this is irrespective of actual winner mode - intra or any of the 4 inter modes 3. For B frame, if winner is Bskip/Bdirect, then both the Bskip motion vectors are used (L0 and L1) 4. For B frame, if winner is other than Bskip/Bdirect, following applies : a. if best 16x16 partition is L0, then use that mv b. if best 16x16 partition is L1, then use that mv c. if best 16x16 partition is bi, then use both L0 and L1 mvs of the 16x16 partition. d. note that for all these cases, the actual winner mode is irrelevant. actual winner mode could be either intra or any of the 4 inter winner modes. 8kx8k has 2^18 MBs. So, 19 bits are at the most required. This is used for PicAFF and adaptive reference field decisions
  [18:0] NUM_STAT_MBS rw
0x1984 __ALL___NUM_STATIC_Y_MBS
  [31:19] RESERVED ro — Same as num_stat_MBs except that this register accumulates MBs on which static check needs to be met only for Y motion vector.
  [18:0] NUM_STAT_Y_MBS rw
0x1988 __ALL___NUM_MVY_INT_MBS
  [31:19] RESERVED ro — Required for adaptive reference field selection Uses L0 refindex 0 frame mv
  [18:0] NUM_MVY_INT_MBS rw
0x198C __ALL___NUM_MVY_HPEL_MBS
  [31:19] RESERVED ro — Required for adaptive reference field selection Uses L0 refindex 0 frame mv
  [18:0] NUM_MVY_HPEL_MBS rw
0x1990 __ALL___NUM_MVY_QPEL_MBS
  [31:19] RESERVED ro — Required for adaptive reference field selection Uses L0 refindex 0 frame mv
  [18:0] NUM_MVY_QPEL_MBS rw
0x1994 __ALL___ACCUM_WINNER_COST_MSW
  [3:0] ACCUM_WINNER_COST_MSW rw
0x1998 __ALL___ACCUM_WINNER_COST_LSW rw
  [31:0] ACCUM_WINNER_COST_LSW — Used for rate control. 24 bit cost for a single macro-block assuming 14bit pixel. 2^18 macro-blocks in 8kx8k frame. This means 42 bits are needed to accumulate total cost. For 8 bit pixel, only 36 bits are needed.
0x199C __ALL___SUM_MVY_HIGH
  [31:2] RESERVED ro — Used for gmv calculation. iME5 accumulates the sum, while iCONT will calculate the average to get the gmv. sum is calculated based on the winner 16x16 sub-pel motion vector for every macro-block in the selected reference frame. Same gmv will be scaled appropriately by iCONT to be used for different reference frames for the future frame. If the 'UseForMVStat' flag is '1' in the RFPB, then winner motion vector in the corresponding reference frame is used for statistic collection. Assuming 8k x 8k resolution, we need to support mvs from -8k to +(8k-0.25). This takes 13+1 + 2(for subpel) = 16 bits each for x and y. 2^18 MBs in each frame means we need 16+18 = 34 bits for each component of the motion vector (x and y). total 68 bits.
  [1:0] SUM_MVY_HIGH rw
0x19A0 __ALL___SUM_MVY_LOW rw
  [31:0] SUM_MVY_LOW
0x19A4 __ALL___SUM_MVX_HIGH
  [1:0] SUM_MVX_HIGH rw
0x19A8 __ALL___SUM_MVX_LOW rw
  [31:0] SUM_MVX_LOW
0x19AC __ALL___SUM_MVY2_HIGH
  [31:18] RESERVED ro — ME is not going to calculate square root. 32 bits are needed to store square for each component. Same motion vector as sum_mv*_* is used. 2^18 MBs in a frame means we need 18 + 16*2 = 50 bits for x and y component each.
  [17:0] SUM_MVY2_HIGH rw
0x19B0 __ALL___SUM_MVY2_LOW rw
  [31:0] SUM_MVY2_LOW
0x19B4 __ALL___SUM_MVX2_HIGH
  [31:18] RESERVED ro — ME is not going to calculate square root. 32 bits are needed to store square for each component. Same motion vector as sum_mv*_* is used. 2^18 MBs in a frame means we need 18 + 16*2 = 50 bits for x and y component each.
  [17:0] SUM_MVX2_HIGH rw
0x19B8 __ALL___SUM_MVX2_LOW rw
  [31:0] SUM_MVX2_LOW
0x19BC __ALL___SUM_ABS_MVY_HIGH
  [1:0] SUM_ABS_MVY_HIGH rw
0x19C0 __ALL___SUM_ABS_MVY_LOW rw
  [31:0] SUM_ABS_MVY_LOW — sum of absolute motion vectors. This is used to figure out whether to use weighted prediction or not. If the motion is very large then the weights calculated do not reliably indicate the change in the luminence. Hence, weighted prediction is disabled. same motion vector as sum_mv*_* is used.
0x19C4 __ALL___SUM_ABS_MVX_HIGH
  [1:0] SUM_ABS_MVX_HIGH rw
0x19C8 __ALL___SUM_ABS_MVX_LOW rw
  [31:0] SUM_ABS_MVX_LOW — sum of absolute motion vectors. This is used to figure out whether to use weighted prediction or not. If the motion is very large then the weights calculated do not reliably indicate the change in the luminence. Hence, weighted prediction is disabled. same motion vector as sum_mv*_* is used.
{0x19CC+0x18*i} __ALL___ROI_SUM_SAD_HI_{i} (i=0..9)
  [3:0] ROI_SUM_SAD_HI_{i} rw
{0x19D0+0x18*i} __ALL___ROI_SUM_SAD_LO_{i} rw (i=0..9)
  [31:0] ROI_SUM_SAD_LO_{i}
{0x19D8+0x18*i} __ALL___ROI_SUM_MVY_LO_{i} rw (i=0..5)
  [31:0] ROI_SUM_MVY_LO_{i}
{0x19E0+0x18*i} __ALL___ROI_SUM_MVX_LO_{i} rw (i=0..9)
  [31:0] ROI_SUM_MVX_LO_{i}
0x1A68 __ALL___ROI_SUM_MVY_LO_6 ro
  [31:0] ROI_SUM_MVY_LO_6
{0x19D8+0x18*i} __ALL___ROI_SUM_MVY_LO_{i} rw (i=7..9)
  [31:0] ROI_SUM_MVY_LO_{i}
0x1ABC __ALL___NUMOFMBSINTER rw
  [31:0] INTERMBS
0x1AC0 __ALL___NUMOFMBSINTRA rw
  [31:0] INTRAMBS
0x1AC4 __ALL___MB_COUTNER1 — counter to generate interrupt after N MB
  [17:0] MB_COUTNER rw — If MB_COUNT_CTRL.EN == 1, incremented first, and then compared against MB_COUNT_CTRL.MAX_COUNT for each MB executed. If compare matches ( && MB_COUNT_CTRL.EN == 1 ), interrupt is signaled to HTS; HTS generates interrupt provided interrupt source enabled after Tend. MB_COUNTER is reset to 0.
0x1AC8 __ALL___MB_COUTNER2 — counter to generate interrupt after N MB
  fields as __ALL___MB_COUTNER1
0x1B00 __ALL___TOP_REFIDX_1
  [31:24] RESERVED ro — There are four buffers for top 4 macro-blocks. They are named _1, _2, _3 and _4. At reset, these correspond to D, B, C and E (E is a new name) where D, B and C are notations from H264 standard. Since these are circular buffers, circular buffer pointer is also provided to determine current status.
  [23:18] TOP_BL_L0_REFIDX rw — [5:2] : refpicture index [1:0] : picture format winner bottom-left L0 refindex 0 : frame picture 1 : top-field picture 2 : bottom-field picture 3 : reserved
  [17:12] TOP_BL_L1_REFIDX rw — winner bottom-left L1 refindex
  [11:6] TOP_BR_L0_REFIDX rw — winner bottom-right L0 refindex
  [5:0] TOP_BR_L1_REFIDX rw — winner bottom-right L1 refindex
0x1B04 __ALL___TOP_BL_L0_MV_1 rw
  [31:16] TOP_BL_L0_MVY_1 — winner bottom-left L0 motion vector
  [15:0] TOP_BL_L0_MVX_1
0x1B08 __ALL___TOP_BL_L1_MV_1 rw
  [31:16] TOP_BL_L1_MVY_1 — winner bottom-left L1 motion vector
  [15:0] TOP_BL_L1_MVX_1
0x1B0C __ALL___TOP_BR_L0_MV_1 rw
  [31:16] TOP_BR_L0_MVY_1 — winner bottom-right L0 motion vector
  [15:0] TOP_BR_L0_MVX_1
0x1B10 __ALL___TOP_BR_L1_MV_1 rw
  [31:16] TOP_BR_L1_MVY_1 — winner bottom-right L1 motion vector
  [15:0] TOP_BR_L1_MVX_1
{0x1AEC+0x14*i} __ALL___TOP_REFIDX_{i} (i=2..4)
  [31:24] RESERVED ro — There are four buffers for top 4 macro-blocks. They are named _1, _2, _3 and _4. At reset, these correspond to D, B, C and E (E is a new name) where D, B and C are notations from H264 standard. Since these are circular buffers, circular buffer pointer is also provided to determine current status.
  [23:18] TOP_BL_L0_REFIDX rw
  [17:12] TOP_BL_L1_REFIDX rw
  [11:6] TOP_BR_L0_REFIDX rw
  [5:0] TOP_BR_L1_REFIDX rw
